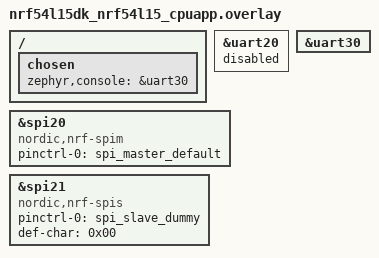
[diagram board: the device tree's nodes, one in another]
#include "../../../common/common-pinctrl.dtsi"

/ {
    chosen {
        zephyr,console = &uart30;
    };
};

&uart20 {
    status = "disabled";
};

&uart30 {
    status = "okay";
};

&spi20 {
    status = "okay";
    compatible = "nordic,nrf-spim";
    pinctrl-0 = <&spi_master_default>;
    pinctrl-names = "default";
};

&spi21 {
    status = "okay";
    compatible =  "nordic,nrf-spis";
    pinctrl-0 = <&spi_slave_dummy>;
    pinctrl-names = "default";
    /delete-property/ rx-delay-supported;
    /delete-property/ rx-delay;
    def-char = <0x00>;
};
